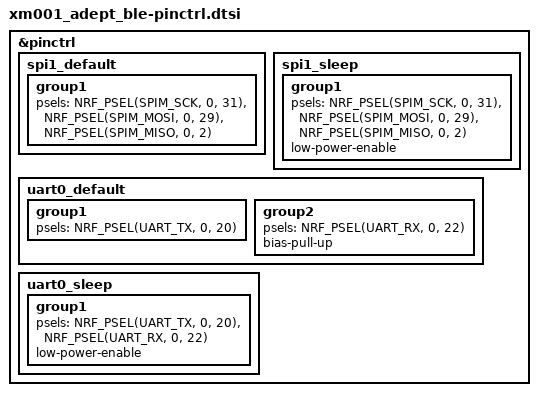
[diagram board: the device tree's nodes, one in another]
/*
 * Pin control for XM001-Adept BLE (EBYTE E73-2G4M08S1C / nRF52833).
 *
 * GPIO numbers in these macros are nRF port pins (P0.x -> 0+x, P1.x -> 32+x),
 * NOT E73 module pad numbers.
 *
 * PMW3610 trackball, read straight out of the PCB netlist
 * (ProDoc_sensor_3_2026-10-11.epro):
 *
 *   sensor pad 3  SCLK  -> net SCLK -> E73 pad 9  = P0.31
 *   sensor pad 2  MOSI  -> net MOSI -> E73 pad 8  = P0.29
 *   sensor pad 8  MISO  -> net MISO -> E73 pad 7  = P0.02
 *   sensor pad 5  CS    -> net CS   -> E73 pad 6  = P1.13
 *
 * NOTE: on this board the nRF pin that carries the CS net is the E73 pad
 * that the module pinout calls P1.09 (pad 17), and the SCLK net sits on
 * P0.31 (pad 9).  The net *names* and the pad *functions* disagree; the
 * netlist above is what is actually routed, so it wins.
 *
 * SPDX-License-Identifier: MIT
 */

&pinctrl {
	spi1_default: spi1_default {
		group1 {
			psels = <NRF_PSEL(SPIM_SCK, 0, 31)>,
				<NRF_PSEL(SPIM_MOSI, 0, 29)>,
				<NRF_PSEL(SPIM_MISO, 0, 2)>;
		};
	};

	spi1_sleep: spi1_sleep {
		group1 {
			psels = <NRF_PSEL(SPIM_SCK, 0, 31)>,
				<NRF_PSEL(SPIM_MOSI, 0, 29)>,
				<NRF_PSEL(SPIM_MISO, 0, 2)>;
			low-power-enable;
		};
	};

	uart0_default: uart0_default {
		group1 {
			psels = <NRF_PSEL(UART_TX, 0, 20)>;
		};
		group2 {
			psels = <NRF_PSEL(UART_RX, 0, 22)>;
			bias-pull-up;
		};
	};

	uart0_sleep: uart0_sleep {
		group1 {
			psels = <NRF_PSEL(UART_TX, 0, 20)>,
				<NRF_PSEL(UART_RX, 0, 22)>;
			low-power-enable;
		};
	};
};
